# RL7005_IP_SVD register map
Vendor: Realtek
Registers are 32-bit, read-write, reset 0x0 unless marked. A register's access mark holds for its fields unless they carry their own. Offsets are from the block's base; [hi:lo] are bit positions; {n}, {i} and the like mark numbered series.

## SDIO
Base 0x40114000
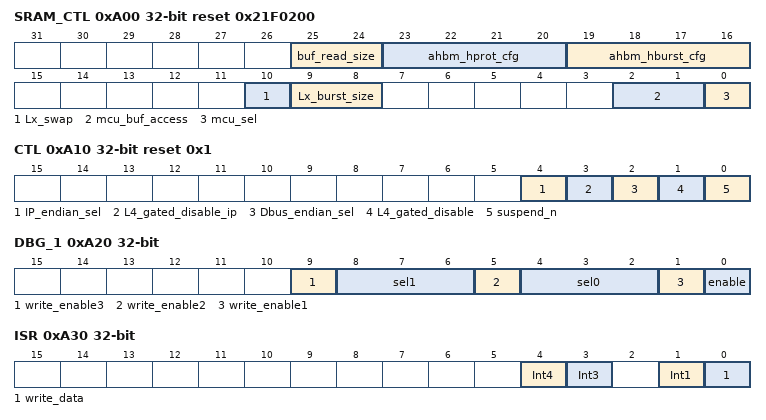
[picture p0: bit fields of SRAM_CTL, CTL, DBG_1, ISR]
0xA00 SRAM_CTL reset 0x21F0200
  [25:24] buf_read_size — Buffer Data Port Read Size (BDPRS) 2'b00: 1-byte access, port_a_rd_ptr increment by 1 2'b01: 2-byte access, port_a_rd_ptr increment by 2 2'b10: 4-byte access, port_a_rd_ptr increment by 4 2'b11: decoding byte enable(BE[3:0]) bus signal If block-size is odd-byte, please set buf_read_size=2'b00
  [23:20] ahbm_hprot_cfg — AHB bus Protection control
  [19:16] ahbm_hburst_cfg — bit[3]: ena_incrx_align: alignment Burst Type enable bit[2]: ena_inc16: INCR16 Burst Type Enable bit[1]: ena_inc8: INCR8 Burst Type Enable bit[0]: ena_inc4: INCR4 Burst Type Enable
  [10] Lx_swap — Reserved
  [9:8] Lx_burst_size — 2'b11: Reserved 2'b10:burst length = 256 bytes (64 Dwords) 2'b01: burst length = 128 bytes (32 Dwords) 2'b00: burst length = 64 bytes (16 Dwords)
  [2:1] mcu_buf_access — in bit[0] = 1 condition, bit[2:1] = 'b00 : buf access disable. bit[2:1] = 'b01 : buf abs access enable, ring buffer address is direct mapping to 0x4005_CB00 ~ 0x4005_CEFF. (mcu_addr[15:0]=0000~3FF, mcu_cs_buf_absolute) bit[2:1] = 'b10: buf auto access enable, ring buffer could be access by register (mcu_addr=FE30~FE33, mcu_cs_buf_auto) 0x4005_CB30 (sram data [7:0]), 0x4005_CB31 (sram data [15:8]), 0x4005_CB32 (sram data [23:16]), 0x4005_CB33 (sram data [31:24]), address will auto increase by 4. bit[2:1] = 'b11 : buf access disable.
  [0] mcu_sel — 0: elbi I/F (dword access for SDIO host standard register) 1: mcu I/F (byte access for SDIO IP register)
0xA10 CTL reset 0x1
  [4] IP_endian_sel — 0:Little; 1:Big
  [3] L4_gated_disable_ip — Disable L4 clock gated for ip
  [2] Dbus_endian_sel — 0: Little; 1: Big
  [1] L4_gated_disable — Disable L4 clock gated
  [0] suspend_n — suspend, low active
0xA20 DBG_1 access per field
  [9] write_enable3 wo — Write enable for bit[8..6]
  [8:6] sel1 rw — Select control of dbg_sel1.
  [5] write_enable2 wo — Write enable for bit[4..2]
  [4:2] sel0 rw — Select control of dbg_sel0.
  [1] write_enable1 wo — Write enable for bit0.
  [0] enable rw — Debug Enable. If set to 1, the debug port will be switched to the selected probed signals for observation. If clear to 0 (default), the scpu_dbg_out0 and scpu_dbg_out1 are both static at h0.
0xA24 DBG_2
  [2:0] dbus_dbg_sel — sdio dbus dbg select
0xA28 DBG_3
  [7:0] ip_dbg_sel — sdio ip dbg select
0xA30 ISR access per field
  [4] Int4 rw — SDIO Int4. SDIO IP Int.
  [3] Int3 rw — SD Int3.SB1 wlast/rlast.
  [1] Int1 rw — SDIO Int1. DMA done.
  [0] write_data wo — 1 to set, 0 to clear bit with 1.
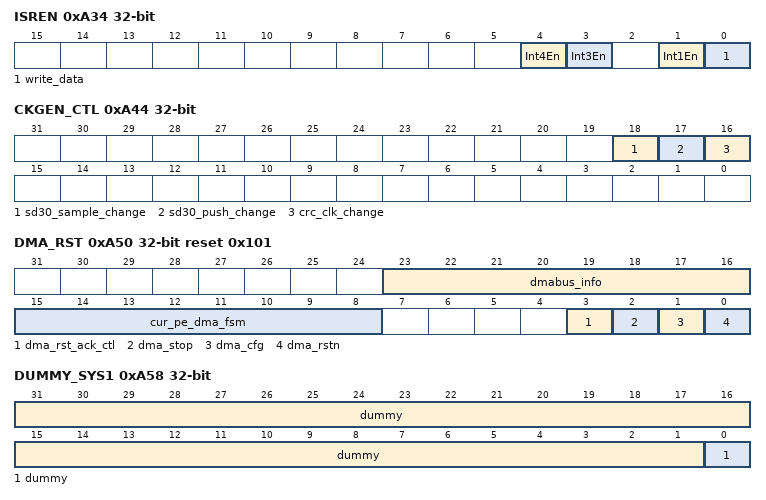
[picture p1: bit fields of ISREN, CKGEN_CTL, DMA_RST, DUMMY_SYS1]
0xA34 ISREN access per field
  [4] Int4En rw — SDIO Int4 Enable IP Int Enable
  [3] Int3En rw — SDIO Int3 Enable SB1 wlast/rlast Int Enable
  [1] Int1En rw — SDIO Int1 Enable Dma done Int Enable
  [0] write_data wo — 1 to set, 0 to clear bit with 1.
0xA44 CKGEN_CTL
  [18] sd30_sample_change — 0: from sd30_sample_clk_src 1: clk
  [17] sd30_push_change — 0: from sd30_push_clk_src 1: clk
  [16] crc_clk_change — 0: from crc_clk_src 1: clk
0xA50 DMA_RST access per field reset 0x101
  [23:16] dmabus_info ro — {1'b0, dma_state[2:0], 1'b0, dbus_state[2:0]} for debug
  [15:8] cur_pe_dma_fsm ro — {1'b0, cur_pe_dma_fsm} for debug
  [3] dma_rst_ack_ctl rw — 1'b0: dma acknowledge soft reset after dbus_req done 1'b1: dma always acknowledge soft reset regardless of dbus_req
  [2] dma_stop rw — Set this bit to stop dma, (suggest running dma_stop before doing software reset to avoid DMA hang)
  [1] dma_cfg rw — Fix software Reset bug on the sdio_dbus module 1'b0: don't soft reset pe_tx_leng_re/pe_rx_leng_re 1'b1: soft reset pe_tx_leng_rx/pe_rx_leng_re
  [0] dma_rstn rw — dma soft reset.
0xA58 DUMMY_SYS1 access per field
  [31:1] dummy rw — Dummy bit.
  [0] dummy ro — Dummy bit.(Reserved)
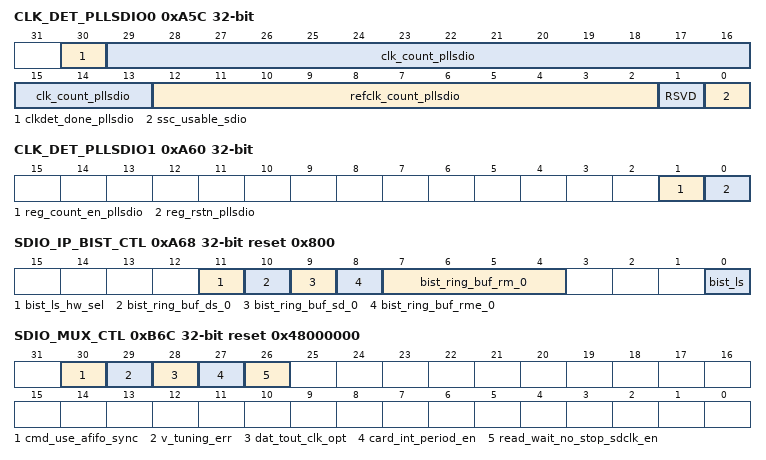
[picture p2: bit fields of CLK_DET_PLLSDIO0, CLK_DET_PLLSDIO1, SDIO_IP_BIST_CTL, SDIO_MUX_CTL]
0xA5C CLK_DET_PLLSDIO0 access per field
  [30] clkdet_done_pllsdio ro — (Reserved)
  [29:13] clk_count_pllsdio ro — (Reserved)
  [12:2] refclk_count_pllsdio ro — (Reserved)
  [1] RSVD wo
  [0] ssc_usable_sdio ro — (Reserved)
0xA60 CLK_DET_PLLSDIO1
  [1] reg_count_en_pllsdio — (Reserved)
  [0] reg_rstn_pllsdio — (Reserved)
0xA68 SDIO_IP_BIST_CTL reset 0x800
  [11] bist_ls_hw_sel — (Reserved)
  [10] bist_ring_buf_ds_0 — (Reserved)
  [9] bist_ring_buf_sd_0 — (Reserved)
  [8] bist_ring_buf_rme_0 — (Reserved)
  [7:4] bist_ring_buf_rm_0 — (Reserved)
  [0] bist_ls — (Reserved)
0xAF0 DUMMY
  [31:0] dummy — Dummy bit.
0xB6C SDIO_MUX_CTL ro reset 0x48000000
  [30] cmd_use_afifo_sync
  [29] v_tuning_err — U Tuning error
  [28] dat_tout_clk_opt — Data Tout clk option
  [27] card_int_period_en — Card int period enable
  [26] read_wait_no_stop_sdclk_en — 1:no stop SD clock when read wait 0:stop SD clock when read wait
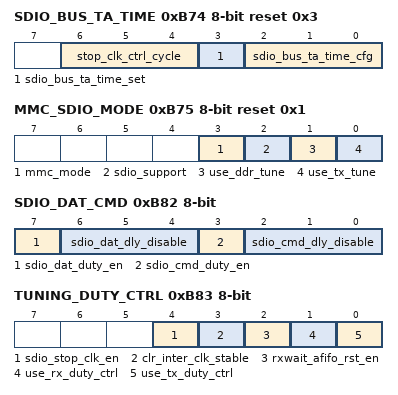
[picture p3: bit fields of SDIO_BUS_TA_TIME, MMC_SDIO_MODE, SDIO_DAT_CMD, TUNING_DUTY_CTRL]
0xB74 SDIO_BUS_TA_TIME 8-bit reset 0x3
  [6:4] stop_clk_ctrl_cycle — stop_clk_ctrl_cycle Stop SDCLK some clocks ahead before receiving the end of the read-block 3'd0: no advance 3'd1:advance 1 clock cycle 3'd2: advance 2 clock cycles The other value more than 2: And so on
  [3] sdio_bus_ta_time_set — Turn-Around Time enable When this bit is b1, Bus_TA_Time(bit[2:0]) is in use. Otherwise HW will determine the bus turn-around time automatically.
  [2:0] sdio_bus_ta_time_cfg — Bus_TA_Time These bits are used to define the number of SDCLK periods that HW should wait for SD bus turn-around time. After sending the end bit of command, HW will wait at least Bus_TA_Time to start to receive the start bit of response from card. After sending the end bit of write block, HW will also wait at least Bus_TA_Time to start to receive the start bit of CRC status from card.
0xB75 MMC_SDIO_MODE 8-bit access per field reset 0x1
  [3] mmc_mode ro
  [2] sdio_support ro
  [1] use_ddr_tune rw — Use DDR Tuning
  [0] use_tx_tune rw — Tuning
0xB76 RX_BEST_PHASE 8-bit ro
  [4:0] rx_best_phase
0xB77 TX_BEST_PHASE 8-bit ro
  [4:0] tx_best_phase — rx_best_phase
{0xB78+i} RX_PHASE_{i} 8-bit ro (i=0..3)
  [7:0] rx_phase_result_{8i+7}_{8i} — rx_phase_result {i}
{0xB7C+i} TX_PHASE_{i} 8-bit ro (i=0..3)
  [7:0] tx_phase_result_{8i+7}_{8i} — tx_phase_result {i}
0xB80 PHASE_RST_TM_0 8-bit ro
  [7:0] phase_rst_time_cfg_7_0 — phase_rst_time_cfg low
0xB81 PHASE_RST_TM_1 8-bit ro reset 0x1
  [3:0] phase_rst_time_cfg_11_8 — phase_rst_time_cfg high
0xB82 SDIO_DAT_CMD 8-bit ro
  [7] sdio_dat_duty_en, [6:4] sdio_dat_dly_disable, [3] sdio_cmd_duty_en, [2:0] sdio_cmd_dly_disable
0xB83 TUNING_DUTY_CTRL 8-bit ro
  [4] sdio_stop_clk_en — Stop SDCLK enable
  [3] clr_inter_clk_stable — Clear Internal CLK Stable
  [2] rxwait_afifo_rst_en — Rx wait AFIFO Reset enable
  [1] use_rx_duty_ctrl — Use RX Duty Control
  [0] use_tx_duty_ctrl — Use TX Duty Control
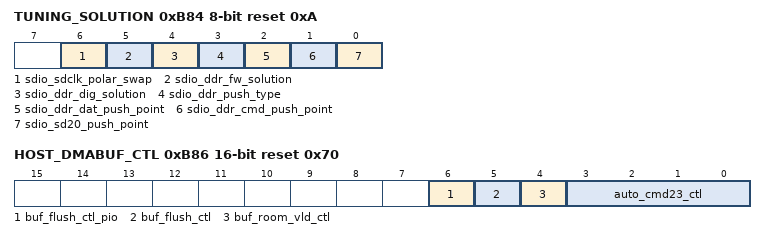
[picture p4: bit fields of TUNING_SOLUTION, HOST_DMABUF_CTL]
0xB84 TUNING_SOLUTION 8-bit ro reset 0xA
  [6] sdio_sdclk_polar_swap — SDIO SDCLK polarity swap
  [5] sdio_ddr_fw_solution — SDIO DDR Digital solution
  [4] sdio_ddr_dig_solution — SDIO DDR FW solution
  [3] sdio_ddr_push_type
  [2] sdio_ddr_dat_push_point — SDIO DDR DAT Push Point 0: set-up time: 1/4 SDCLK cycle; hold time: 1/4 SDCLK cycle, sd20_dato (trigged by crc_clk rising edge) 1: set-up time: 1/2 SDCLK cycle; hold time: 0 SDCLK cycle, sd30_dato (trigged by crc_clk falling edge)
  [1] sdio_ddr_cmd_push_point — SDIO DDR CMD Push Point 0: output at falling edge of SDCLK(set-up time: 1/2 SDCLK cycle; hold time: 1/2 SDCLK cycle), sd30_cmdo (trigged by crc_clk falling edge) 1: output is ahead by 1/4 SDCLK period(set-up time: 3/4 SDCLK cycle; hold time: 1/4 SDCLK cycle), sd20_cmdo (trigged by crc_clk rising edge)
  [0] sdio_sd20_push_point — SDIO SD20 Push Point 0: output at falling edge of SDCLK(set-up time: 1/2 SDCLK cycle; hold time: 1/2 SDCLK cycle), sd20_cmdo/sd20_dato (trigged by crc_clk rising edge) 1: output is ahead by 1/4 SDCLK period(set-up time: 3/4 SDCLK cycle; hold time: 1/4 SDCLK cycle), sd30_cmdo/sd30_dato (trigged by crc_clk falling edge)
0xB85 SD_SAMPLE_POINT_CTL 8-bit
  [3] sd20_samp_point — Sample Point Selection for SD20 CMD / DATA 0: sample at rising edge of SDCLK 1: sample point is delayed by 1/4 SDCLK period
0xB86 HOST_DMABUF_CTL 16-bit reset 0x70
  [6] buf_flush_ctl_pio — buf_flush_ctl_pio (2020/10/12) 0: don't flush PCIE_RING_BUF and reset rd_ptr/wr_ptr at PIO mode xxxxxx 1: auto-flush PCIE_RING_BUF and reset rd_prt/wr_ptr after each block transfer complete at PIO Mode
  [5] buf_flush_ctl — buf_flush_ctl (2020/09/04) 0: don't flush PCIE_RING_BUF and reset rd_ptr/wr_ptr at DMA mode 1: auto-flush PCIE_RING_BUF and reset rd_ptr/wr_ptr after each SDIO data transfer (to fix the same sram address read-write collision) at DMA Mode
  [4] buf_room_vld_ctl — buf_room_vld_ctl (2020/09/01) 0: byte-level buf_room_vld control 1: Qword-level(8-byte) buf_room_vld control to fix the PCIE_RING_BUF bug when ADMA length not equal to the multiple of 8 (to fix the same sram address read-write collision)
  [3:0] auto_cmd23_ctl — Auto Cmd23 error control 0: auto cmd23 response error stop next command transfer 1:auto cmd23 response error doesn't stop next command transfer
